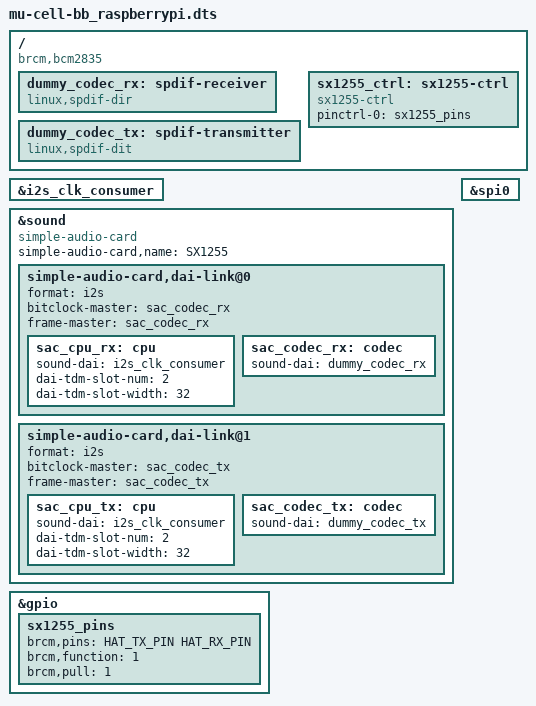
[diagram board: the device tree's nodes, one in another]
// SPDX-License-Identifier: MIT
/dts-v1/;
/plugin/;

#ifndef HAT_TX_PIN
#define HAT_TX_PIN 22
#endif
#ifndef HAT_RX_PIN
#define HAT_RX_PIN 23
#endif

/ {
	compatible = "brcm,bcm2835";

	fragment@0 {
		target = <&i2s_clk_consumer>;
		__overlay__ { status = "okay"; };
	};

	fragment@1 {
		target-path = "/";
		__overlay__ {
			dummy_codec_rx: spdif-receiver {
				compatible = "linux,spdif-dir";
				status = "okay";
				#sound-dai-cells = <0>;
			};
			dummy_codec_tx: spdif-transmitter {
				compatible = "linux,spdif-dit";
				status = "okay";
				#sound-dai-cells = <0>;
			};
		};
	};

	fragment@2 {
		target = <&sound>;
		__overlay__ {
			compatible = "simple-audio-card";
			status = "okay";
			simple-audio-card,name = "SX1255";

			simple-audio-card,dai-link@0 {
				format = "i2s";
				bitclock-master = <&sac_codec_rx>;
				frame-master = <&sac_codec_rx>;
				sac_cpu_rx: cpu {
					sound-dai = <&i2s_clk_consumer>;
					dai-tdm-slot-num = <2>;
					dai-tdm-slot-width = <32>;
				};
				sac_codec_rx: codec {
					sound-dai = <&dummy_codec_rx>;
				};
			};

			simple-audio-card,dai-link@1 {
				format = "i2s";
				bitclock-master = <&sac_codec_tx>;
				frame-master = <&sac_codec_tx>;
				sac_cpu_tx: cpu {
					sound-dai = <&i2s_clk_consumer>;
					dai-tdm-slot-num = <2>;
					dai-tdm-slot-width = <32>;
				};
				sac_codec_tx: codec {
					sound-dai = <&dummy_codec_tx>;
				};
			};
		};
	};

	fragment@3 {
		target = <&spi0>;
		__overlay__ { status = "okay"; };
	};

	fragment@4 {
		target = <&gpio>;
		__overlay__ {
			sx1255_pins: sx1255_pins {
				brcm,pins = <HAT_TX_PIN HAT_RX_PIN>;
				brcm,function = <1>;  /* output */
				brcm,pull = <1>;      /* pull-down */
			};
		};
	};

	fragment@5 {
		target-path = "/";
		__overlay__ {
			sx1255_ctrl: sx1255-ctrl {
				compatible = "sx1255-ctrl";
				pinctrl-names = "default";
				pinctrl-0 = <&sx1255_pins>;
			};
		};
	};
};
